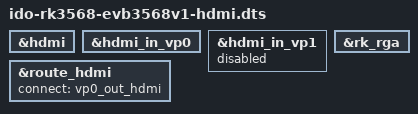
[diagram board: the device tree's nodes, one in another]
// SPDX-License-Identifier: (GPL-2.0+ OR MIT)
/*
 * Copyright (c) 2020 Rockchip Electronics Co., Ltd.
 *
 */

/dts-v1/;

#include "ido-rk3568-evb3568v1.dts"

&hdmi {
	status = "okay";
};

&hdmi_in_vp0 {
	status = "okay";
};

&hdmi_in_vp1 {
	status = "disabled";
};

&route_hdmi {
	status = "okay";
	connect = <&vp0_out_hdmi>;
};

&rk_rga {
	status = "okay";
};
